# MK22FA12 register map
Vendor: Freescale Semiconductor, Inc.; Series: Kinetis_K; File version: 1.6
CPU: CM4 r0p1, little endian, no MPU, FPU, VTOR, 4 interrupt priority bits
Registers are 32-bit, read-write, reset 0x0 unless marked. A register's access mark holds for its fields unless they carry their own. Offsets are from the block's base; [hi:lo] are bit positions; {n}, {i} and the like mark numbered series; 'fields as' and 'values as' point back to an identical list.

## AXBS — Crossbar switch
Base 0x40004000; register names take the prefix AXBS_
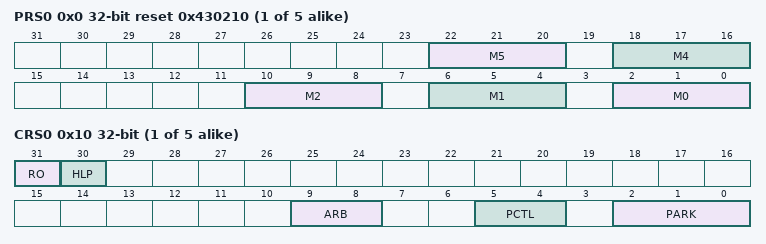
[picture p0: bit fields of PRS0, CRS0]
{0x0+0x100*i} PRS{i} (i=0..4) reset 0x430210 — Priority Registers Slave
  [all] fields
    0=This master has level 1, or highest, priority when accessing the slave port; {v}=This master has level {v+1} priority when accessing the slave port (v=1..6); 7=This master has level 8, or lowest, priority when accessing the slave port
  [22:20] M5 — Master 5 Priority. Sets the arbitration priority for this port on the associated slave port.
  [18:16] M4 — Master 4 Priority. Sets the arbitration priority for this port on the associated slave port.
  [10:8] M2 — Master 2 Priority. Sets the arbitration priority for this port on the associated slave port.
  [6:4] M1 — Master 1 Priority. Sets the arbitration priority for this port on the associated slave port.
  [2:0] M0 — Master 0 Priority. Sets the arbitration priority for this port on the associated slave port.
{0x10+0x100*i} CRS{i} (i=0..4) — Control Register
  [31] RO — Read Only
    0=The slave port's registers are writeable; 1=The slave port's registers are read-only and cannot be written. Attempted writes have no effect on the registers and result in a bus error response.
  [30] HLP — Halt Low Priority
    0=The low power mode request has the highest priority for arbitration on this slave port; 1=The low power mode request has the lowest initial priority for arbitration on this slave port
  [9:8] ARB — Arbitration Mode
    0=Fixed priority; 1=Round-robin, or rotating, priority
  [5:4] PCTL — Parking Control
    0=When no master makes a request, the arbiter parks the slave port on the master port defined by the PARK field; 1=When no master makes a request, the arbiter parks the slave port on the last master to be in control of the slave port; 2=When no master makes a request, the slave port is not parked on a master and the arbiter drives all outputs to a constant safe state
  [2:0] PARK
    {v}=Park on master port M{v} (v=0..7)
{0x800+0x100*i} MGPCR{i} (i=0..2) — Master General Purpose Control Register
  [2:0] AULB — Arbitrates On Undefined Length Bursts
    0=No arbitration is allowed during an undefined length burst; 1=Arbitration is allowed at any time during an undefined length burst; 2=Arbitration is allowed after four beats of an undefined length burst; 3=Arbitration is allowed after eight beats of an undefined length burst; 4=Arbitration is allowed after 16 beats of an undefined length burst
0xC00 MGPCR4 — Master General Purpose Control Register
  fields as MGPCR0
0xD00 MGPCR5 — Master General Purpose Control Register
  fields as MGPCR0

## DMAMUX — DMA channel multiplexor
Base 0x40021000; register names take the prefix DMAMUX_
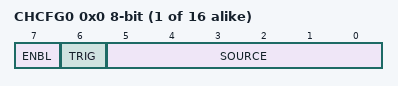
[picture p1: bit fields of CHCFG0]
{0x0+i} CHCFG{i} (i=0..15) 8-bit — Channel Configuration register
  [7] ENBL — DMA Channel Enable
    0=DMA channel is disabled. This mode is primarily used during configuration of the DMAMux. The DMA has separate channel enables/disables, which should be used to disable or reconfigure a DMA channel.; 1=DMA channel is enabled
  [6] TRIG — DMA Channel Trigger Enable
    0=Triggering is disabled. If triggering is disabled and ENBL is set, the DMA Channel will simply route the specified source to the DMA channel. (Normal mode); 1=Triggering is enabled. If triggering is enabled and ENBL is set, the DMAMUX is in Periodic Trigger mode.
  [5:0] SOURCE — DMA Channel Source (Slot)

## CRC — Cyclic Redundancy Check
Base 0x40032000; register names take the prefix CRC_
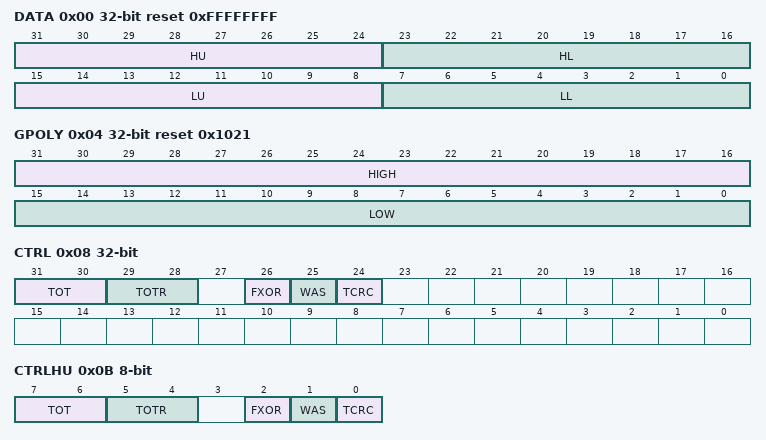
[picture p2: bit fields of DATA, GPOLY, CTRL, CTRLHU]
0x00 DATA reset 0xFFFFFFFF (CRC view) — CRC Data register
  [31:24] HU — CRC High Upper Byte
  [23:16] HL — CRC High Lower Byte
  [15:8] LU — CRC Low Upper Byte
  [7:0] LL — CRC Low Lower Byte
0x00 DATAL 16-bit reset 0xFFFF (CRC view) — CRC_DATAL register.
  [15:0] DATAL — DATAL stores the lower 16 bits of the 16/32 bit CRC
0x00 DATALL 8-bit reset 0xFF (CRC view) — CRC_DATALL register.
  [7:0] DATALL — CRCLL stores the first 8 bits of the 32 bit DATA
0x01 DATALU 8-bit reset 0xFF — CRC_DATALU register.
  [7:0] DATALU — DATALL stores the second 8 bits of the 32 bit CRC
0x02 DATAH 16-bit reset 0xFFFF (CRC view) — CRC_DATAH register.
  [15:0] DATAH — DATAH stores the high 16 bits of the 16/32 bit CRC
0x02 DATAHL 8-bit reset 0xFF (CRC view) — CRC_DATAHL register.
  [7:0] DATAHL — DATAHL stores the third 8 bits of the 32 bit CRC
0x03 DATAHU 8-bit reset 0xFF — CRC_DATAHU register.
  [7:0] DATAHU — DATAHU stores the fourth 8 bits of the 32 bit CRC
0x04 GPOLY reset 0x1021 (CRC view) — CRC Polynomial register
  [31:16] HIGH — High Polynominal Half-word
  [15:0] LOW — Low Polynominal Half-word
0x04 GPOLYL 16-bit reset 0xFFFF (CRC view) — CRC_GPOLYL register.
  [15:0] GPOLYL — POLYL stores the lower 16 bits of the 16/32 bit CRC polynomial value
0x04 GPOLYLL 8-bit reset 0xFF (CRC view) — CRC_GPOLYLL register.
  [7:0] GPOLYLL — POLYLL stores the first 8 bits of the 32 bit CRC
0x05 GPOLYLU 8-bit reset 0xFF — CRC_GPOLYLU register.
  [7:0] GPOLYLU — POLYLL stores the second 8 bits of the 32 bit CRC
0x06 GPOLYH 16-bit reset 0xFFFF (CRC view) — CRC_GPOLYH register.
  [15:0] GPOLYH — POLYH stores the high 16 bits of the 16/32 bit CRC polynomial value
0x06 GPOLYHL 8-bit reset 0xFF (CRC view) — CRC_GPOLYHL register.
  [7:0] GPOLYHL — POLYHL stores the third 8 bits of the 32 bit CRC
0x07 GPOLYHU 8-bit reset 0xFF — CRC_GPOLYHU register.
  [7:0] GPOLYHU — POLYHU stores the fourth 8 bits of the 32 bit CRC
0x08 CTRL — CRC Control register
  [31:30] TOT — Type Of Transpose For Writes
    0=No transposition; 1=Bits in bytes are transposed; bytes are not transposed; 2=Both bits in bytes and bytes are transposed; 3=Only bytes are transposed; no bits in a byte are transposed
  [29:28] TOTR — Type Of Transpose For Read
    values as TOT
  [26] FXOR — Complement Read Of CRC Data Register
    0=No XOR on reading; 1=Invert or complement the read value of the CRC Data register
  [25] WAS — Write CRC Data Register As Seed
    0=Writes to the CRC data register are data values; 1=Writes to the CRC data register are seed values
  [24] TCRC — Width of CRC protocol.
    0=16-bit CRC protocol; 1=32-bit CRC protocol
0x0B CTRLHU 8-bit — CRC_CTRLHU register.
  [7:6] TOT
    0=No Transposition; 1=Bits in bytes are transposed, bytes are not transposed; 2=Both bits in bytes and bytes are transposed; 3=Only bytes are transposed; no bits in a byte are transposed
  [5:4] TOTR
    values as TOT
  [2] FXOR
    0=No XOR on reading; 1=Invert or complement the read value of CRC data register
  [1] WAS
    0=Writes to CRC data register are data values; 1=Writes to CRC data reguster are seed values
  [0] TCRC
    0=16-bit CRC protocol; 1=32-bit CRC protocol
